AUTOSAR XML (schema 4-2-2)
package /Base_SWC
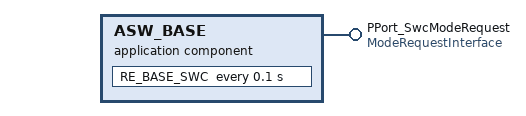
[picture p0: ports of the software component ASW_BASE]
  application sw component type ASW_BASE
    provide port PPort_SwcModeRequest: provided-interface=ModeRequestInterface
    behavior IB_Base_SWC: data-type-mapping=AppMode_Mapping
      timing event TE_Base_SWC_100ms: start-on-event=RE_BASE_SWC, period=0.1
      runnable RE_BASE_SWC: mode-access-point=currentMode, symbol=RE_BASE_SWC_func
        data-send-points:
          access DSP_AppMode_0: accessed-variable=PPort_SwcModeRequest.AppMode
  sender receiver interface DataTransfer100Byte_From100msTaskTo10msTask
    data Data_ptr: type=Array100ByteDataElement
  impl type Array100ByteDataElement: category=ARRAY
    element DataElement: array-size=100, implementation-data-type=uint8
  sender receiver interface DataTransfer100Byte_Core0Core1
    data Data_ptr: type=Array100ByteDataElement
  client server interface Core_ClientServer_Interface: is-service=true
    operation Core_ClientServer
      arg CoreStatus: type=uint16, direction=OUT
      arg Data2Core: type=uint16, direction=IN
      arg DataOfCore: type=uint16, direction=OUT
